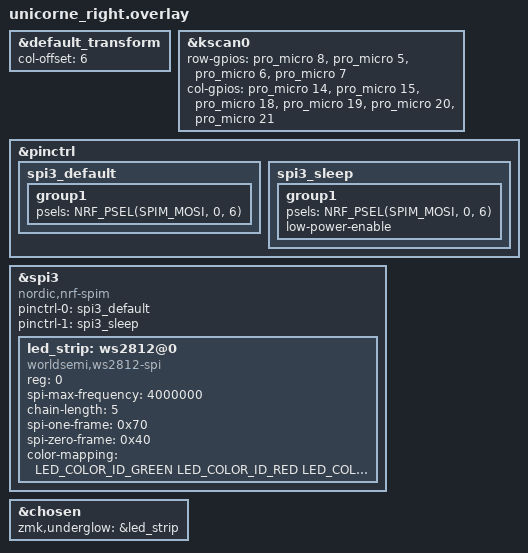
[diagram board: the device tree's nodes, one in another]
#include "unicorne.dtsi"
#include <dt-bindings/led/led.h>

&default_transform {
    col-offset = <6>;
};

&kscan0 {
    row-gpios
      = <&pro_micro 8 (GPIO_ACTIVE_HIGH | GPIO_PULL_DOWN)>
      , <&pro_micro 5 (GPIO_ACTIVE_HIGH | GPIO_PULL_DOWN)>
      , <&pro_micro 6 (GPIO_ACTIVE_HIGH | GPIO_PULL_DOWN)>
      , <&pro_micro 7 (GPIO_ACTIVE_HIGH | GPIO_PULL_DOWN)>
      ;

    col-gpios
        = <&pro_micro 14 GPIO_ACTIVE_HIGH>
        , <&pro_micro 15 GPIO_ACTIVE_HIGH>
        , <&pro_micro 18 GPIO_ACTIVE_HIGH>
        , <&pro_micro 19 GPIO_ACTIVE_HIGH>
        , <&pro_micro 20 GPIO_ACTIVE_HIGH>
        , <&pro_micro 21 GPIO_ACTIVE_HIGH>
        ;
};

&pinctrl {
    spi3_default: spi3_default {
        group1 {
            psels = <NRF_PSEL(SPIM_MOSI, 0, 6)>;
        };
    };

    spi3_sleep: spi3_sleep {
        group1 {
            psels = <NRF_PSEL(SPIM_MOSI, 0, 6)>;
            low-power-enable;
        };
    };
};

&spi3 {
    compatible = "nordic,nrf-spim";
    status = "okay";
    pinctrl-0 = <&spi3_default>;
    pinctrl-1 = <&spi3_sleep>;
    pinctrl-names = "default", "sleep";

    led_strip: ws2812@0 {
        compatible = "worldsemi,ws2812-spi";
        reg = <0>;
        spi-max-frequency = <4000000>;
        chain-length = <5>;
        spi-one-frame = <0x70>;
        spi-zero-frame = <0x40>;
        color-mapping = <LED_COLOR_ID_GREEN LED_COLOR_ID_RED LED_COLOR_ID_BLUE>;
    };
};

&chosen {
        zmk,underglow = &led_strip;
};

// &i2c0 {
//     status = "okay";

//     oled: ssd1306@3c {
//         compatible = "solomon,ssd1306fb";
//         reg = <0x3c>;
//         width = <128>;
//         height = <32>;
//         segment-offset = <0>;
//         page-offset = <0>;
//         display-offset = <0>;
//         multiplex-ratio = <31>;
//         prechargep = <0x22>;
//     };
// };
